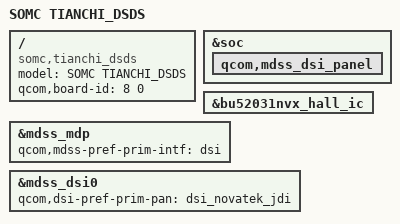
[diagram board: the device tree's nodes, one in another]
/* Copyright (c) 2013, The Linux Foundation. All rights reserved.
 * Copyright (C) 2014 Sony Mobile Communications AB.
 *
 * This program is free software; you can redistribute it and/or modify
 * it under the terms of the GNU General Public License version 2 and
 * only version 2 as published by the Free Software Foundation.
 *
 * This program is distributed in the hope that it will be useful,
 * but WITHOUT ANY WARRANTY; without even the implied warranty of
 * MERCHANTABILITY or FITNESS FOR A PARTICULAR PURPOSE.  See the
 * GNU General Public License for more details.
 *
 * NOTE: This file has been modified by Sony Mobile Communications AB.
 * Modifications are licensed under the License.
 */

/dts-v1/;
/include/ "msm8226-v2-tianchi_dsds.dtsi"
/include/ "msm8226-tianchi_dsds.dtsi"
/include/ "dsi-tianchi_dsds-panel.dtsi"
/include/ "msm8226-camera-sensor-tianchi.dtsi"

/ {
	model = "SOMC TIANCHI_DSDS";
	compatible = "somc,tianchi_dsds", "qcom,msm8226", "qcom,mtp";
	qcom,board-id = <8 0>;
};

&soc {
        qcom,mdss_dsi_panel {
                status = "ok";
        };
};

&bu52031nvx_hall_ic {
	status = "ok";
};

&mdss_mdp {
	qcom,mdss-pref-prim-intf = "dsi";
};

&mdss_dsi0 {
	qcom,dsi-pref-prim-pan = <&dsi_novatek_jdi>;
};
